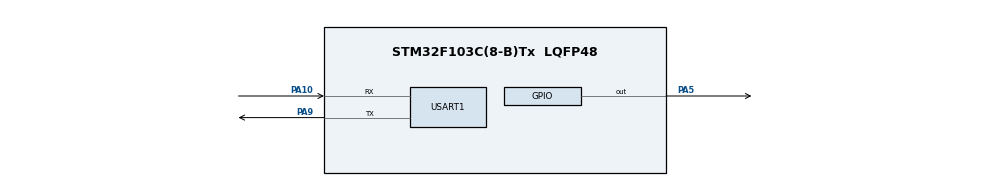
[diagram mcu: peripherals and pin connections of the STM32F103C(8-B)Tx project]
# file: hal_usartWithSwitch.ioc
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Mcu.Family=STM32F1
Mcu.Name=STM32F103C(8-B)Tx
Mcu.Package=LQFP48
NVIC.PriorityGroup=NVIC_PRIORITYGROUP_4
NVIC.USART1_IRQn=true\:0\:0\:false\:false\:true\:true\:true
PA10.Mode=Asynchronous
PA10.Signal=USART1_RX
PA5.Signal=GPIO_Output
PA9.Mode=Asynchronous
PA9.Signal=USART1_TX
ProjectManager.HeapSize=0x200
ProjectManager.StackSize=0x400
ProjectManager.TargetToolchain=MDK-ARM V5.32
RCC.APB1Freq_Value=8000000
RCC.APB2Freq_Value=8000000
USART1.VirtualMode=VM_ASYNC
VP_SYS_VS_ND.Mode=No_Debug
board=custom

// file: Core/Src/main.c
/* USER CODE BEGIN Header */
/**
  ******************************************************************************
  * @file           : main.c
  * @brief          : Main program body
  ******************************************************************************
  * @attention
  *
  * Copyright (c) 2022 STMicroelectronics.
  * All rights reserved.
  *
  * This software is licensed under terms that can be found in the LICENSE file
  * in the root directory of this software component.
  * If no LICENSE file comes with this software, it is provided AS-IS.
  *
  ******************************************************************************
  */
/* USER CODE END Header */
#include "main.h"
#include "usart.h"
#include "gpio.h"

void SystemClock_Config(void);

/* USER CODE BEGIN 0 */

int strEqual(char rcData[15],char rcData2[15]){
	for(uint8_t i = 0 ; i < 15 ; i++){
		if (rcData[i] != rcData2[i]) return 0;
	}
	return 1;
}
/* USER CODE END 0 */

int main(void)
{

	//uint8_t rcFlag;

  /* MCU Configuration--------------------------------------------------------*/

  /* Reset of all peripherals, Initializes the Flash interface and the Systick. */
  HAL_Init();

  /* Configure the system clock */
  SystemClock_Config();

  /* Initialize all configured peripherals */
  MX_GPIO_Init();
  MX_USART1_UART_Init();
  /* USER CODE BEGIN 2 */
	//HAL_UART_Receive_IT(&huart1,&rcData,1);
  /* USER CODE END 2 */

  /* Infinite loop */
  /* USER CODE BEGIN WHILE */
	//HAL_UART_Receive_IT(&huart1,(uint8_t*)rcData,15);
	char rcData[15] = "hello windows!";
  while (1)
  {
		HAL_UART_Receive_IT(&huart1,(uint8_t*)rcData,14);
    /* USER CODE END WHILE */
		if(strEqual(rcData,"stop stm32!   ")){
			HAL_GPIO_WritePin(GPIOA,GPIO_PIN_5,GPIO_PIN_SET);
		}
		else if(strEqual(rcData,"hello windows!")){
			HAL_GPIO_WritePin(GPIOA,GPIO_PIN_5,GPIO_PIN_RESET);
			uint8_t hello[20]="hello world\n";
			HAL_UART_Transmit_IT(&huart1,hello,20);
			HAL_Delay(1000);
		}
  }
}
void SystemClock_Config(void)
{
  RCC_OscInitTypeDef RCC_OscInitStruct = {0};
  RCC_ClkInitTypeDef RCC_ClkInitStruct = {0};

  /** Initializes the RCC Oscillators according to the specified parameters
  * in the RCC_OscInitTypeDef structure.
  */
  RCC_OscInitStruct.OscillatorType = RCC_OSCILLATORTYPE_HSI;
  RCC_OscInitStruct.HSIState = RCC_HSI_ON;
  RCC_OscInitStruct.HSICalibrationValue = RCC_HSICALIBRATION_DEFAULT;
  RCC_OscInitStruct.PLL.PLLState = RCC_PLL_NONE;
  if (HAL_RCC_OscConfig(&RCC_OscInitStruct) != HAL_OK)
  {
    Error_Handler();
  }
  /** Initializes the CPU, AHB and APB buses clocks
  */
  RCC_ClkInitStruct.ClockType = RCC_CLOCKTYPE_HCLK|RCC_CLOCKTYPE_SYSCLK
                              |RCC_CLOCKTYPE_PCLK1|RCC_CLOCKTYPE_PCLK2;
  RCC_ClkInitStruct.SYSCLKSource = RCC_SYSCLKSOURCE_HSI;
  RCC_ClkInitStruct.AHBCLKDivider = RCC_SYSCLK_DIV1;
  RCC_ClkInitStruct.APB1CLKDivider = RCC_HCLK_DIV1;
  RCC_ClkInitStruct.APB2CLKDivider = RCC_HCLK_DIV1;

  if (HAL_RCC_ClockConfig(&RCC_ClkInitStruct, FLASH_LATENCY_0) != HAL_OK)
  {
    Error_Handler();
  }
}

/* USER CODE BEGIN 4 */
//void HAL_UART_RxCpltCallback(UART_HandleTypeDef *huart){
//	if (huart->Instance == USART1){
//		//while(HAL_UART_Receive_IT(&huart1,(uint8_t*)rcData,15) != HAL_OK);
//		HAL_UART_Receive_IT(&huart1,(uint8_t*)rcData,15);
//	}
//}
/* USER CODE END 4 */

void Error_Handler(void)
{
  __disable_irq();
  while (1)
  {
  }
}
